AUTOSAR XML (schema 4-0-3)
package /CalibrationComponents
  parameter sw component type SOPR: data-type-mapping=SOPR_CodeDataTypeMappingsSet
    provide port SOPR_Pport: provided-interface=SOPR_if
      provided-com-specs:
        init-value=0, parameter=KeSOPR_I_ChrgCurLmt_Val
        init-value=0, parameter=KeSOPR_I_DschgCurLmt_Val
        init-value=0, parameter=KeSOPR_kE_InitialTotalChargeEnergy
        init-value=0, parameter=KeSOPR_kE_InitialTotalDisChargeEnergy
        init-value=0, parameter=KeSOPR_kE_InitialTotalFeedbackEnergy
        init-value=0, parameter=KeSOPR_kE_OvrdValue_SingleChargeEnergy
        init-value=0, parameter=KeSOPR_kE_OvrdValue_SingleDisChargeEnergy
        init-value=0, parameter=KeSOPR_kE_OvrdValue_SingleFeedbackEnergy
        init-value=0, parameter=KeSOPR_kE_OvrdValue_TotalChargeEnergy
        init-value=0, parameter=KeSOPR_kE_OvrdValue_TotalDisChargeEnergy
        init-value=0, parameter=KeSOPR_kE_OvrdValue_TotalFeedbackEnergy
        init-value=655, parameter=KeSOPR_kE_SingleChargeEnergy_MaxVal
        init-value=0, parameter=KeSOPR_kE_SingleChargeEnergy_minVal
        init-value=655, parameter=KeSOPR_kE_SingleDisChargeEnergy_MaxVal
        init-value=0, parameter=KeSOPR_kE_SingleDisChargeEnergy_minVal
        init-value=655, parameter=KeSOPR_kE_SingleFeedbackEnergy_MaxVal
        init-value=0, parameter=KeSOPR_kE_SingleFeedbackEnergy_minVal
        init-value=104857, parameter=KeSOPR_kE_TotalChargeEnergy_MaxVal
        init-value=0, parameter=KeSOPR_kE_TotalChargeEnergy_minVal
        init-value=1677721, parameter=KeSOPR_kE_TotalDisChargeEnergy_MaxVal
        init-value=0, parameter=KeSOPR_kE_TotalDisChargeEnergy_minVal
        init-value=104857, parameter=KeSOPR_kE_TotalFeedbackEnergy_MaxVal
        init-value=0, parameter=KeSOPR_kE_TotalFeedbackEnergy_minVal
        init-value=0, parameter=KeSOPR_kP_ChrgPwrLmtInst_Val
        init-value=200, parameter=KeSOPR_kP_ChrgPwrLmt_MaxVal
        init-value=0, parameter=KeSOPR_kP_ChrgPwrLmt_Val
        init-value=0, parameter=KeSOPR_kP_ChrgPwrLmt_minVal
        init-value=0, parameter=KeSOPR_kP_DschgPwrLmtInst_Val
        init-value=200, parameter=KeSOPR_kP_DschgPwrLmt_MaxVal
        init-value=0, parameter=KeSOPR_kP_DschgPwrLmt_Val
        init-value=0, parameter=KeSOPR_kP_DschgPwrLmt_minVal
        init-value=9, parameter=KeSOPR_kP_LimitedSOP_Value
        init-value=0, parameter=KeSOPR_kP_OverPower_Reset
        init-value=0.6600000262260437, parameter=KeSOPR_kP_OverPower_Set
        init-value=0, parameter=KeSOPR_kP_PackInstantOutPower_Val
        init-value=0, parameter=KeSOPR_kP_PackInstantRecoveryPower_Val
        init-value=0, parameter=KeSOPR_kP_PackRealTimePower_Val
        init-value=0.5, parameter=KeSOPR_kP_SlewRateLimitPer20ms
        init-value=1.0499999523162842, parameter=KeSOPR_k_CoefRatedPower1_Set
        init-value=1.100000023841858, parameter=KeSOPR_k_CoefRatedPower2_Set
        init-value=1.2000000476837158, parameter=KeSOPR_k_CoefRatedPower3_Set
        init-value=1, parameter=KeSOPR_k_CoefRatedPower_Reset
        init-value=0.20000000298023224, parameter=KeSOPR_t_DTCTimer1_Set
        init-value=0.20000000298023224, parameter=KeSOPR_t_DTCTimer2_Set
        init-value=3, parameter=KeSOPR_t_DTCTimer_Reset
        init-value=0.30000001192092896, parameter=KeSOPR_t_DelayDischarge10Kw
        init-value=0.019999999552965164, parameter=KeSOPR_t_SR_SOPR
        init-value=0, parameter=KeSOPR_b_ChrgCurLmt_Ctrl
        init-value=0, parameter=KeSOPR_b_ChrgPwrLmtInst_Ctrl
        init-value=0, parameter=KeSOPR_b_ChrgPwrLmt_Ctrl
        init-value=0, parameter=KeSOPR_b_DschgCurLmt_Ctrl
        init-value=0, parameter=KeSOPR_b_DschgPwrLmtInst_Ctrl
        init-value=0, parameter=KeSOPR_b_DschgPwrLmt_Ctrl
        init-value=0, parameter=KeSOPR_b_OvrdCond_SingleChargeEnergy
        init-value=0, parameter=KeSOPR_b_OvrdCond_SingleDisChargeEnergy
        init-value=0, parameter=KeSOPR_b_OvrdCond_SingleFeedbackEnergy
        init-value=0, parameter=KeSOPR_b_OvrdCond_TotalChargeEnergy
        init-value=0, parameter=KeSOPR_b_OvrdCond_TotalDisChargeEnergy
        init-value=0, parameter=KeSOPR_b_OvrdCond_TotalFeedbackEnergy
        init-value=0, parameter=KeSOPR_b_PackInstantOutPower_Ctrl
        init-value=0, parameter=KeSOPR_b_PackInstantRecoveryPower_Ctrl
        init-value=0, parameter=KeSOPR_b_PackOverChrgPower{1..3}_flt_En
        init-value=0, parameter=KeSOPR_b_PackOverChrgPower_Rank_CAN_En
        init-value=0, parameter=KeSOPR_b_PackOverDchrgPower{1..3}_flt_En
        init-value=0, parameter=KeSOPR_b_PackOverDchrgPower_Rank_CAN_En
        init-value=0, parameter=KeSOPR_b_PackRealTimePower_Ctrl
        init-value=0, parameter=KeSOPR_k_PackOverChrgPower{1..3}_flt_Val
        init-value=0, parameter=KeSOPR_k_PackOverChrgPower_Rank_CAN_Val
        init-value=0, parameter=KeSOPR_k_PackOverDchrgPower{1..3}_flt_Val
        init-value=0, parameter=KeSOPR_k_PackOverDchrgPower_Rank_CAN_Val
package /SOPR_Code_pkg/SOPR_Code_swc
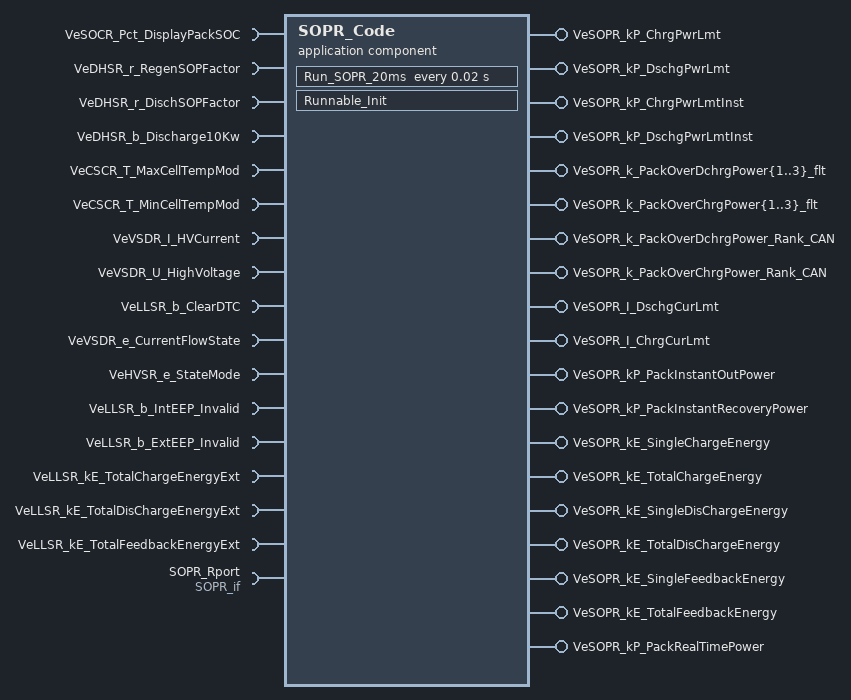
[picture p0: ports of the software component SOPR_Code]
  application sw component type SOPR_Code
    16 x require port:
      VeSOCR_Pct_DisplayPackSOC: nonqueued-receiver-com-spec{data-element=VeSOCR_Pct_DisplayPackSOC, init-value=0}, required-interface=VeSOCR_Pct_DisplayPackSOC
      VeDHSR_r_RegenSOPFactor: nonqueued-receiver-com-spec{data-element=VeDHSR_r_RegenSOPFactor, init-value=0}, required-interface=VeDHSR_r_RegenSOPFactor
      VeDHSR_r_DischSOPFactor: nonqueued-receiver-com-spec{data-element=VeDHSR_r_DischSOPFactor, init-value=0}, required-interface=VeDHSR_r_DischSOPFactor
      VeDHSR_b_Discharge10Kw: nonqueued-receiver-com-spec{data-element=VeDHSR_b_Discharge10Kw, init-value=0}, required-interface=VeDHSR_b_Discharge10Kw
      VeCSCR_T_MaxCellTempMod: nonqueued-receiver-com-spec{data-element=VeCSCR_T_MaxCellTempMod, init-value=0}, required-interface=VeCSCR_T_MaxCellTempMod
      VeCSCR_T_MinCellTempMod: nonqueued-receiver-com-spec{data-element=VeCSCR_T_MinCellTempMod, init-value=0}, required-interface=VeCSCR_T_MinCellTempMod
      VeVSDR_I_HVCurrent: nonqueued-receiver-com-spec{data-element=VeVSDR_I_HVCurrent, init-value=0}, required-interface=VeVSDR_I_HVCurrent
      VeVSDR_U_HighVoltage: nonqueued-receiver-com-spec{data-element=VeVSDR_U_HighVoltage, init-value=0}, required-interface=VeVSDR_U_HighVoltage
      VeLLSR_b_ClearDTC: nonqueued-receiver-com-spec{data-element=VeLLSR_b_ClearDTC, init-value=0}, required-interface=VeLLSR_b_ClearDTC
      VeVSDR_e_CurrentFlowState: nonqueued-receiver-com-spec{data-element=VeVSDR_e_CurrentFlowState, init-value=CeVSDR_e_CurFlowStateInit}, required-interface=VeVSDR_e_CurrentFlowState
      VeHVSR_e_StateMode: nonqueued-receiver-com-spec{data-element=VeHVSR_e_StateMode, init-value=CeHVSR_e_StateModeReserved}, required-interface=VeHVSR_e_StateMode
      VeLLSR_b_IntEEP_Invalid: nonqueued-receiver-com-spec{data-element=VeLLSR_b_IntEEP_Invalid, init-value=0}, required-interface=VeLLSR_b_IntEEP_Invalid
      VeLLSR_b_ExtEEP_Invalid: nonqueued-receiver-com-spec{data-element=VeLLSR_b_ExtEEP_Invalid, init-value=0}, required-interface=VeLLSR_b_ExtEEP_Invalid
      VeLLSR_kE_TotalChargeEnergyExt: nonqueued-receiver-com-spec{data-element=VeLLSR_kE_TotalChargeEnergyExt, init-value=0}, required-interface=VeLLSR_kE_TotalChargeEnergyExt
      VeLLSR_kE_TotalDisChargeEnergyExt: nonqueued-receiver-com-spec{data-element=VeLLSR_kE_TotalDisChargeEnergyExt, init-value=0}, required-interface=VeLLSR_kE_TotalDisChargeEnergyExt
      VeLLSR_kE_TotalFeedbackEnergyExt: nonqueued-receiver-com-spec{data-element=VeLLSR_kE_TotalFeedbackEnergyExt, init-value=0}, required-interface=VeLLSR_kE_TotalFeedbackEnergyExt
    23 x provide port:
      VeSOPR_kP_ChrgPwrLmt: nonqueued-sender-com-spec{data-element=VeSOPR_kP_ChrgPwrLmt, init-value=0}, provided-interface=VeSOPR_kP_ChrgPwrLmt
      VeSOPR_kP_DschgPwrLmt: nonqueued-sender-com-spec{data-element=VeSOPR_kP_DschgPwrLmt, init-value=0}, provided-interface=VeSOPR_kP_DschgPwrLmt
      VeSOPR_kP_ChrgPwrLmtInst: nonqueued-sender-com-spec{data-element=VeSOPR_kP_ChrgPwrLmtInst, init-value=0}, provided-interface=VeSOPR_kP_ChrgPwrLmtInst
      VeSOPR_kP_DschgPwrLmtInst: nonqueued-sender-com-spec{data-element=VeSOPR_kP_DschgPwrLmtInst, init-value=0}, provided-interface=VeSOPR_kP_DschgPwrLmtInst
      VeSOPR_k_PackOverDchrgPower{1..3}_flt: nonqueued-sender-com-spec{data-element=VeSOPR_k_PackOverDchrgPower{1..3}_flt, init-value=0}, provided-interface=VeSOPR_k_PackOverDchrgPower{1..3}_flt
      VeSOPR_k_PackOverChrgPower{1..3}_flt: nonqueued-sender-com-spec{data-element=VeSOPR_k_PackOverChrgPower{1..3}_flt, init-value=0}, provided-interface=VeSOPR_k_PackOverChrgPower{1..3}_flt
      VeSOPR_k_PackOverDchrgPower_Rank_CAN: nonqueued-sender-com-spec{data-element=VeSOPR_k_PackOverDchrgPower_Rank_CAN, init-value=0}, provided-interface=VeSOPR_k_PackOverDchrgPower_Rank_CAN
      VeSOPR_k_PackOverChrgPower_Rank_CAN: nonqueued-sender-com-spec{data-element=VeSOPR_k_PackOverChrgPower_Rank_CAN, init-value=0}, provided-interface=VeSOPR_k_PackOverChrgPower_Rank_CAN
      VeSOPR_I_DschgCurLmt: nonqueued-sender-com-spec{data-element=VeSOPR_I_DschgCurLmt, init-value=0}, provided-interface=VeSOPR_I_DschgCurLmt
      VeSOPR_I_ChrgCurLmt: nonqueued-sender-com-spec{data-element=VeSOPR_I_ChrgCurLmt, init-value=0}, provided-interface=VeSOPR_I_ChrgCurLmt
      VeSOPR_kP_PackInstantOutPower: nonqueued-sender-com-spec{data-element=VeSOPR_kP_PackInstantOutPower, init-value=0}, provided-interface=VeSOPR_kP_PackInstantOutPower
      VeSOPR_kP_PackInstantRecoveryPower: nonqueued-sender-com-spec{data-element=VeSOPR_kP_PackInstantRecoveryPower, init-value=0}, provided-interface=VeSOPR_kP_PackInstantRecoveryPower
      VeSOPR_kE_SingleChargeEnergy: nonqueued-sender-com-spec{data-element=VeSOPR_kE_SingleChargeEnergy, init-value=0}, provided-interface=VeSOPR_kE_SingleChargeEnergy
      VeSOPR_kE_TotalChargeEnergy: nonqueued-sender-com-spec{data-element=VeSOPR_kE_TotalChargeEnergy, init-value=0}, provided-interface=VeSOPR_kE_TotalChargeEnergy
      VeSOPR_kE_SingleDisChargeEnergy: nonqueued-sender-com-spec{data-element=VeSOPR_kE_SingleDisChargeEnergy, init-value=0}, provided-interface=VeSOPR_kE_SingleDisChargeEnergy
      VeSOPR_kE_TotalDisChargeEnergy: nonqueued-sender-com-spec{data-element=VeSOPR_kE_TotalDisChargeEnergy, init-value=0}, provided-interface=VeSOPR_kE_TotalDisChargeEnergy
      VeSOPR_kE_SingleFeedbackEnergy: nonqueued-sender-com-spec{data-element=VeSOPR_kE_SingleFeedbackEnergy, init-value=0}, provided-interface=VeSOPR_kE_SingleFeedbackEnergy
      VeSOPR_kE_TotalFeedbackEnergy: nonqueued-sender-com-spec{data-element=VeSOPR_kE_TotalFeedbackEnergy, init-value=0}, provided-interface=VeSOPR_kE_TotalFeedbackEnergy
      VeSOPR_kP_PackRealTimePower: nonqueued-sender-com-spec{data-element=VeSOPR_kP_PackRealTimePower, init-value=0}, provided-interface=VeSOPR_kP_PackRealTimePower
    require port SOPR_Rport: required-interface=SOPR_if
    behavior SOPR_Code: data-type-mapping=SOPR_CodeDataTypeMappingsSet, handle-termination-and-restart=NO-SUPPORT
      exclusive area EA_NeSOPR_kE_TotalDisChargeEnergy
      exclusive area EA_NeSOPR_kE_TotalFeedbackEnergy
      exclusive area EA_NeSOPR_kE_TotalChargeEnergy
      timing event Event_Run_SOPR_20ms: start-on-event=Run_SOPR_20ms, period=0.02
      per instance memory NeSOPR_kE_TotalDisChargeEnergy: implementation-data-type=Float, type=NeSOPR_kE_TotalDisChargeEnergy_Float, type-definition=Float
      per instance memory NeSOPR_kE_TotalFeedbackEnergy: implementation-data-type=Float, type=NeSOPR_kE_TotalFeedbackEnergy_Float, type-definition=Float
      per instance memory NeSOPR_kE_TotalChargeEnergy: implementation-data-type=Float, type=NeSOPR_kE_TotalChargeEnergy_Float, type-definition=Float
      runnable Runnable_Init: symbol=SOPR_Code_Init
      runnable Run_SOPR_20ms: runs-inside-exclusive-area=[EA_NeSOPR_kE_TotalChargeEnergy, EA_NeSOPR_kE_TotalDisChargeEnergy, EA_NeSOPR_kE_TotalFeedbackEnergy]
        data-read-access:
          16 x access:
            IN_VeCSCR_T_MaxCellTempMod_VeCSCR_T_MaxCellTempMod: accessed-variable=VeCSCR_T_MaxCellTempMod.VeCSCR_T_MaxCellTempMod
            IN_VeCSCR_T_MinCellTempMod_VeCSCR_T_MinCellTempMod: accessed-variable=VeCSCR_T_MinCellTempMod.VeCSCR_T_MinCellTempMod
            IN_VeDHSR_b_Discharge10Kw_VeDHSR_b_Discharge10Kw: accessed-variable=VeDHSR_b_Discharge10Kw.VeDHSR_b_Discharge10Kw
            IN_VeDHSR_r_DischSOPFactor_VeDHSR_r_DischSOPFactor: accessed-variable=VeDHSR_r_DischSOPFactor.VeDHSR_r_DischSOPFactor
            IN_VeDHSR_r_RegenSOPFactor_VeDHSR_r_RegenSOPFactor: accessed-variable=VeDHSR_r_RegenSOPFactor.VeDHSR_r_RegenSOPFactor
            IN_VeHVSR_e_StateMode_VeHVSR_e_StateMode: accessed-variable=VeHVSR_e_StateMode.VeHVSR_e_StateMode
            IN_VeLLSR_b_ClearDTC_VeLLSR_b_ClearDTC: accessed-variable=VeLLSR_b_ClearDTC.VeLLSR_b_ClearDTC
            IN_VeLLSR_b_ExtEEP_Invalid_VeLLSR_b_ExtEEP_Invalid: accessed-variable=VeLLSR_b_ExtEEP_Invalid.VeLLSR_b_ExtEEP_Invalid
            IN_VeLLSR_b_IntEEP_Invalid_VeLLSR_b_IntEEP_Invalid: accessed-variable=VeLLSR_b_IntEEP_Invalid.VeLLSR_b_IntEEP_Invalid
            IN_VeLLSR_kE_TotalChargeEnergyExt_VeLLSR_kE_T_5df67a94075a893a: accessed-variable=VeLLSR_kE_TotalChargeEnergyExt.VeLLSR_kE_TotalChargeEnergyExt
            IN_VeLLSR_kE_TotalDisChargeEnergyExt_VeLLSR_k_0328c4f008460225: accessed-variable=VeLLSR_kE_TotalDisChargeEnergyExt.VeLLSR_kE_TotalDisChargeEnergyExt
            IN_VeLLSR_kE_TotalFeedbackEnergyExt_VeLLSR_kE_f88ecd803695f56f: accessed-variable=VeLLSR_kE_TotalFeedbackEnergyExt.VeLLSR_kE_TotalFeedbackEnergyExt
            IN_VeSOCR_Pct_DisplayPackSOC_VeSOCR_Pct_DisplayPackSOC: accessed-variable=VeSOCR_Pct_DisplayPackSOC.VeSOCR_Pct_DisplayPackSOC
            IN_VeVSDR_I_HVCurrent_VeVSDR_I_HVCurrent: accessed-variable=VeVSDR_I_HVCurrent.VeVSDR_I_HVCurrent
            IN_VeVSDR_U_HighVoltage_VeVSDR_U_HighVoltage: accessed-variable=VeVSDR_U_HighVoltage.VeVSDR_U_HighVoltage
            IN_VeVSDR_e_CurrentFlowState_VeVSDR_e_CurrentFlowState: accessed-variable=VeVSDR_e_CurrentFlowState.VeVSDR_e_CurrentFlowState
        data-send-points:
          23 x access:
            OUT_VeSOPR_kP_ChrgPwrLmt_VeSOPR_kP_ChrgPwrLmt: accessed-variable=VeSOPR_kP_ChrgPwrLmt.VeSOPR_kP_ChrgPwrLmt
            OUT_VeSOPR_kP_DschgPwrLmt_VeSOPR_kP_DschgPwrLmt: accessed-variable=VeSOPR_kP_DschgPwrLmt.VeSOPR_kP_DschgPwrLmt
            OUT_VeSOPR_kP_ChrgPwrLmtInst_VeSOPR_kP_ChrgPwrLmtInst: accessed-variable=VeSOPR_kP_ChrgPwrLmtInst.VeSOPR_kP_ChrgPwrLmtInst
            OUT_VeSOPR_kP_DschgPwrLmtInst_VeSOPR_kP_DschgPwrLmtInst: accessed-variable=VeSOPR_kP_DschgPwrLmtInst.VeSOPR_kP_DschgPwrLmtInst
            OUT_VeSOPR_k_PackOverDchrgPower1_flt_VeSOPR_k_084e043cabe95846: accessed-variable=VeSOPR_k_PackOverDchrgPower1_flt.VeSOPR_k_PackOverDchrgPower1_flt
            OUT_VeSOPR_k_PackOverDchrgPower2_flt_VeSOPR_k_9a63996ecbb8c152: accessed-variable=VeSOPR_k_PackOverDchrgPower2_flt.VeSOPR_k_PackOverDchrgPower2_flt
            OUT_VeSOPR_k_PackOverDchrgPower3_flt_VeSOPR_k_f3b3028557801532: accessed-variable=VeSOPR_k_PackOverDchrgPower3_flt.VeSOPR_k_PackOverDchrgPower3_flt
            OUT_VeSOPR_k_PackOverChrgPower1_flt_VeSOPR_k_bafdb95f1384b1c6: accessed-variable=VeSOPR_k_PackOverChrgPower1_flt.VeSOPR_k_PackOverChrgPower1_flt
            OUT_VeSOPR_k_PackOverChrgPower2_flt_VeSOPR_k_718ddc91b4fe7bda: accessed-variable=VeSOPR_k_PackOverChrgPower2_flt.VeSOPR_k_PackOverChrgPower2_flt
            OUT_VeSOPR_k_PackOverChrgPower3_flt_VeSOPR_k_da0a8855b1c881eb: accessed-variable=VeSOPR_k_PackOverChrgPower3_flt.VeSOPR_k_PackOverChrgPower3_flt
            OUT_VeSOPR_k_PackOverDchrgPower_Rank_CAN_VeSO_a530ebaf238aaa7d: accessed-variable=VeSOPR_k_PackOverDchrgPower_Rank_CAN.VeSOPR_k_PackOverDchrgPower_Rank_CAN
            OUT_VeSOPR_k_PackOverChrgPower_Rank_CAN_VeSOP_13a80a9a90f45aca: accessed-variable=VeSOPR_k_PackOverChrgPower_Rank_CAN.VeSOPR_k_PackOverChrgPower_Rank_CAN
            OUT_VeSOPR_I_DschgCurLmt_VeSOPR_I_DschgCurLmt: accessed-variable=VeSOPR_I_DschgCurLmt.VeSOPR_I_DschgCurLmt
            OUT_VeSOPR_I_ChrgCurLmt_VeSOPR_I_ChrgCurLmt: accessed-variable=VeSOPR_I_ChrgCurLmt.VeSOPR_I_ChrgCurLmt
            OUT_VeSOPR_kP_PackInstantOutPower_VeSOPR_kP_P_323630c1f9671d55: accessed-variable=VeSOPR_kP_PackInstantOutPower.VeSOPR_kP_PackInstantOutPower
            OUT_VeSOPR_kP_PackInstantRecoveryPower_VeSOPR_f42613d02ba8428d: accessed-variable=VeSOPR_kP_PackInstantRecoveryPower.VeSOPR_kP_PackInstantRecoveryPower
            OUT_VeSOPR_kE_SingleChargeEnergy_VeSOPR_kE_SingleChargeEnergy: accessed-variable=VeSOPR_kE_SingleChargeEnergy.VeSOPR_kE_SingleChargeEnergy
            OUT_VeSOPR_kE_TotalChargeEnergy_VeSOPR_kE_TotalChargeEnergy: accessed-variable=VeSOPR_kE_TotalChargeEnergy.VeSOPR_kE_TotalChargeEnergy
            OUT_VeSOPR_kE_SingleDisChargeEnergy_VeSOPR_kE_0744e4b55030a507: accessed-variable=VeSOPR_kE_SingleDisChargeEnergy.VeSOPR_kE_SingleDisChargeEnergy
            OUT_VeSOPR_kE_TotalDisChargeEnergy_VeSOPR_kE_ed764fddd891b2d9: accessed-variable=VeSOPR_kE_TotalDisChargeEnergy.VeSOPR_kE_TotalDisChargeEnergy
            OUT_VeSOPR_kE_SingleFeedbackEnergy_VeSOPR_kE_44262c0c73e49981: accessed-variable=VeSOPR_kE_SingleFeedbackEnergy.VeSOPR_kE_SingleFeedbackEnergy
            OUT_VeSOPR_kE_TotalFeedbackEnergy_VeSOPR_kE_T_c839511a63296a08: accessed-variable=VeSOPR_kE_TotalFeedbackEnergy.VeSOPR_kE_TotalFeedbackEnergy
            OUT_VeSOPR_kP_PackRealTimePower_VeSOPR_kP_PackRealTimePower: accessed-variable=VeSOPR_kP_PackRealTimePower.VeSOPR_kP_PackRealTimePower
        75 x parameter access:
          CALPRM_SOPR_Rport_KeSOPR_I_ChrgCurLmt_Val: accessed-parameter=SOPR_Rport.KeSOPR_I_ChrgCurLmt_Val
          CALPRM_SOPR_Rport_KeSOPR_I_DschgCurLmt_Val: accessed-parameter=SOPR_Rport.KeSOPR_I_DschgCurLmt_Val
          CALPRM_SOPR_Rport_KeSOPR_b_ChrgCurLmt_Ctrl: accessed-parameter=SOPR_Rport.KeSOPR_b_ChrgCurLmt_Ctrl
          CALPRM_SOPR_Rport_KeSOPR_b_ChrgPwrLmtInst_Ctrl: accessed-parameter=SOPR_Rport.KeSOPR_b_ChrgPwrLmtInst_Ctrl
          CALPRM_SOPR_Rport_KeSOPR_b_ChrgPwrLmt_Ctrl: accessed-parameter=SOPR_Rport.KeSOPR_b_ChrgPwrLmt_Ctrl
          CALPRM_SOPR_Rport_KeSOPR_b_DschgCurLmt_Ctrl: accessed-parameter=SOPR_Rport.KeSOPR_b_DschgCurLmt_Ctrl
          CALPRM_SOPR_Rport_KeSOPR_b_DschgPwrLmtInst_Ctrl: accessed-parameter=SOPR_Rport.KeSOPR_b_DschgPwrLmtInst_Ctrl
          CALPRM_SOPR_Rport_KeSOPR_b_DschgPwrLmt_Ctrl: accessed-parameter=SOPR_Rport.KeSOPR_b_DschgPwrLmt_Ctrl
          CALPRM_SOPR_Rport_KeSOPR_b_OvrdCond_SingleChargeEnergy: accessed-parameter=SOPR_Rport.KeSOPR_b_OvrdCond_SingleChargeEnergy
          CALPRM_SOPR_Rport_KeSOPR_b_OvrdCond_SingleDisChargeEnergy: accessed-parameter=SOPR_Rport.KeSOPR_b_OvrdCond_SingleDisChargeEnergy
          CALPRM_SOPR_Rport_KeSOPR_b_OvrdCond_SingleFeedbackEnergy: accessed-parameter=SOPR_Rport.KeSOPR_b_OvrdCond_SingleFeedbackEnergy
          CALPRM_SOPR_Rport_KeSOPR_b_OvrdCond_TotalChargeEnergy: accessed-parameter=SOPR_Rport.KeSOPR_b_OvrdCond_TotalChargeEnergy
          CALPRM_SOPR_Rport_KeSOPR_b_OvrdCond_TotalDisChargeEnergy: accessed-parameter=SOPR_Rport.KeSOPR_b_OvrdCond_TotalDisChargeEnergy
          CALPRM_SOPR_Rport_KeSOPR_b_OvrdCond_TotalFeedbackEnergy: accessed-parameter=SOPR_Rport.KeSOPR_b_OvrdCond_TotalFeedbackEnergy
          CALPRM_SOPR_Rport_KeSOPR_b_PackInstantOutPower_Ctrl: accessed-parameter=SOPR_Rport.KeSOPR_b_PackInstantOutPower_Ctrl
          CALPRM_SOPR_Rport_KeSOPR_b_PackInstantRecoveryPower_Ctrl: accessed-parameter=SOPR_Rport.KeSOPR_b_PackInstantRecoveryPower_Ctrl
          CALPRM_SOPR_Rport_KeSOPR_b_PackOverChrgPower{1..3}_flt_En: accessed-parameter=SOPR_Rport.KeSOPR_b_PackOverChrgPower{1..3}_flt_En
          CALPRM_SOPR_Rport_KeSOPR_b_PackOverChrgPower_Rank_CAN_En: accessed-parameter=SOPR_Rport.KeSOPR_b_PackOverChrgPower_Rank_CAN_En
          CALPRM_SOPR_Rport_KeSOPR_b_PackOverDchrgPower{1..3}_flt_En: accessed-parameter=SOPR_Rport.KeSOPR_b_PackOverDchrgPower{1..3}_flt_En
          CALPRM_SOPR_Rport_KeSOPR_b_PackOverDchrgPower_Rank_CAN_En: accessed-parameter=SOPR_Rport.KeSOPR_b_PackOverDchrgPower_Rank_CAN_En
          CALPRM_SOPR_Rport_KeSOPR_b_PackRealTimePower_Ctrl: accessed-parameter=SOPR_Rport.KeSOPR_b_PackRealTimePower_Ctrl
          CALPRM_SOPR_Rport_KeSOPR_kE_OvrdValue_SingleChargeEnergy: accessed-parameter=SOPR_Rport.KeSOPR_kE_OvrdValue_SingleChargeEnergy
          CALPRM_SOPR_Rport_KeSOPR_kE_OvrdValue_SingleDisChargeEnergy: accessed-parameter=SOPR_Rport.KeSOPR_kE_OvrdValue_SingleDisChargeEnergy
          CALPRM_SOPR_Rport_KeSOPR_kE_OvrdValue_SingleFeedbackEnergy: accessed-parameter=SOPR_Rport.KeSOPR_kE_OvrdValue_SingleFeedbackEnergy
          CALPRM_SOPR_Rport_KeSOPR_kE_OvrdValue_TotalChargeEnergy: accessed-parameter=SOPR_Rport.KeSOPR_kE_OvrdValue_TotalChargeEnergy
          CALPRM_SOPR_Rport_KeSOPR_kE_OvrdValue_TotalDisChargeEnergy: accessed-parameter=SOPR_Rport.KeSOPR_kE_OvrdValue_TotalDisChargeEnergy
          CALPRM_SOPR_Rport_KeSOPR_kE_OvrdValue_TotalFeedbackEnergy: accessed-parameter=SOPR_Rport.KeSOPR_kE_OvrdValue_TotalFeedbackEnergy
          CALPRM_SOPR_Rport_KeSOPR_kE_SingleChargeEnergy_MaxVal: accessed-parameter=SOPR_Rport.KeSOPR_kE_SingleChargeEnergy_MaxVal
          CALPRM_SOPR_Rport_KeSOPR_kE_SingleChargeEnergy_minVal: accessed-parameter=SOPR_Rport.KeSOPR_kE_SingleChargeEnergy_minVal
          CALPRM_SOPR_Rport_KeSOPR_kE_SingleDisChargeEnergy_MaxVal: accessed-parameter=SOPR_Rport.KeSOPR_kE_SingleDisChargeEnergy_MaxVal
          CALPRM_SOPR_Rport_KeSOPR_kE_SingleDisChargeEnergy_minVal: accessed-parameter=SOPR_Rport.KeSOPR_kE_SingleDisChargeEnergy_minVal
          CALPRM_SOPR_Rport_KeSOPR_kE_SingleFeedbackEnergy_MaxVal: accessed-parameter=SOPR_Rport.KeSOPR_kE_SingleFeedbackEnergy_MaxVal
          CALPRM_SOPR_Rport_KeSOPR_kE_SingleFeedbackEnergy_minVal: accessed-parameter=SOPR_Rport.KeSOPR_kE_SingleFeedbackEnergy_minVal
          CALPRM_SOPR_Rport_KeSOPR_kE_TotalChargeEnergy_MaxVal: accessed-parameter=SOPR_Rport.KeSOPR_kE_TotalChargeEnergy_MaxVal
          CALPRM_SOPR_Rport_KeSOPR_kE_TotalChargeEnergy_minVal: accessed-parameter=SOPR_Rport.KeSOPR_kE_TotalChargeEnergy_minVal
          CALPRM_SOPR_Rport_KeSOPR_kE_TotalDisChargeEnergy_MaxVal: accessed-parameter=SOPR_Rport.KeSOPR_kE_TotalDisChargeEnergy_MaxVal
          CALPRM_SOPR_Rport_KeSOPR_kE_TotalDisChargeEnergy_minVal: accessed-parameter=SOPR_Rport.KeSOPR_kE_TotalDisChargeEnergy_minVal
          CALPRM_SOPR_Rport_KeSOPR_kE_TotalFeedbackEnergy_MaxVal: accessed-parameter=SOPR_Rport.KeSOPR_kE_TotalFeedbackEnergy_MaxVal
          CALPRM_SOPR_Rport_KeSOPR_kE_TotalFeedbackEnergy_minVal: accessed-parameter=SOPR_Rport.KeSOPR_kE_TotalFeedbackEnergy_minVal
          CALPRM_SOPR_Rport_KeSOPR_kP_ChrgPwrLmtInst_Val: accessed-parameter=SOPR_Rport.KeSOPR_kP_ChrgPwrLmtInst_Val
          CALPRM_SOPR_Rport_KeSOPR_kP_ChrgPwrLmt_MaxVal: accessed-parameter=SOPR_Rport.KeSOPR_kP_ChrgPwrLmt_MaxVal
          CALPRM_SOPR_Rport_KeSOPR_kP_ChrgPwrLmt_Val: accessed-parameter=SOPR_Rport.KeSOPR_kP_ChrgPwrLmt_Val
          CALPRM_SOPR_Rport_KeSOPR_kP_ChrgPwrLmt_minVal: accessed-parameter=SOPR_Rport.KeSOPR_kP_ChrgPwrLmt_minVal
          CALPRM_SOPR_Rport_KeSOPR_kP_DschgPwrLmtInst_Val: accessed-parameter=SOPR_Rport.KeSOPR_kP_DschgPwrLmtInst_Val
          CALPRM_SOPR_Rport_KeSOPR_kP_DschgPwrLmt_MaxVal: accessed-parameter=SOPR_Rport.KeSOPR_kP_DschgPwrLmt_MaxVal
          CALPRM_SOPR_Rport_KeSOPR_kP_DschgPwrLmt_Val: accessed-parameter=SOPR_Rport.KeSOPR_kP_DschgPwrLmt_Val
          CALPRM_SOPR_Rport_KeSOPR_kP_DschgPwrLmt_minVal: accessed-parameter=SOPR_Rport.KeSOPR_kP_DschgPwrLmt_minVal
          CALPRM_SOPR_Rport_KeSOPR_kP_LimitedSOP_Value: accessed-parameter=SOPR_Rport.KeSOPR_kP_LimitedSOP_Value
          CALPRM_SOPR_Rport_KeSOPR_kP_OverPower_Reset: accessed-parameter=SOPR_Rport.KeSOPR_kP_OverPower_Reset
          CALPRM_SOPR_Rport_KeSOPR_kP_OverPower_Set: accessed-parameter=SOPR_Rport.KeSOPR_kP_OverPower_Set
          CALPRM_SOPR_Rport_KeSOPR_kP_PackInstantOutPower_Val: accessed-parameter=SOPR_Rport.KeSOPR_kP_PackInstantOutPower_Val
          CALPRM_SOPR_Rport_KeSOPR_kP_PackInstantRecoveryPower_Val: accessed-parameter=SOPR_Rport.KeSOPR_kP_PackInstantRecoveryPower_Val
          CALPRM_SOPR_Rport_KeSOPR_kP_PackRealTimePower_Val: accessed-parameter=SOPR_Rport.KeSOPR_kP_PackRealTimePower_Val
          CALPRM_SOPR_Rport_KeSOPR_kP_SlewRateLimitPer20ms: accessed-parameter=SOPR_Rport.KeSOPR_kP_SlewRateLimitPer20ms
          CALPRM_SOPR_Rport_KeSOPR_k_CoefRatedPower{1..3}_Set: accessed-parameter=SOPR_Rport.KeSOPR_k_CoefRatedPower{1..3}_Set
          CALPRM_SOPR_Rport_KeSOPR_k_CoefRatedPower_Reset: accessed-parameter=SOPR_Rport.KeSOPR_k_CoefRatedPower_Reset
          CALPRM_SOPR_Rport_KeSOPR_k_PackOverChrgPower{1..3}_flt_Val: accessed-parameter=SOPR_Rport.KeSOPR_k_PackOverChrgPower{1..3}_flt_Val
          CALPRM_SOPR_Rport_KeSOPR_k_PackOverChrgPower_Rank_CAN_Val: accessed-parameter=SOPR_Rport.KeSOPR_k_PackOverChrgPower_Rank_CAN_Val
          CALPRM_SOPR_Rport_KeSOPR_k_PackOverDchrgPower{1..3}_flt_Val: accessed-parameter=SOPR_Rport.KeSOPR_k_PackOverDchrgPower{1..3}_flt_Val
          CALPRM_SOPR_Rport_KeSOPR_k_PackOverDchrgPower_Rank_CAN_Val: accessed-parameter=SOPR_Rport.KeSOPR_k_PackOverDchrgPower_Rank_CAN_Val
          CALPRM_SOPR_Rport_KeSOPR_t_DTCTimer1_Set: accessed-parameter=SOPR_Rport.KeSOPR_t_DTCTimer1_Set
          CALPRM_SOPR_Rport_KeSOPR_t_DTCTimer2_Set: accessed-parameter=SOPR_Rport.KeSOPR_t_DTCTimer2_Set
          CALPRM_SOPR_Rport_KeSOPR_t_DTCTimer_Reset: accessed-parameter=SOPR_Rport.KeSOPR_t_DTCTimer_Reset
          CALPRM_SOPR_Rport_KeSOPR_t_DelayDischarge10Kw: accessed-parameter=SOPR_Rport.KeSOPR_t_DelayDischarge10Kw
          CALPRM_SOPR_Rport_KeSOPR_t_SR_SOPR: accessed-parameter=SOPR_Rport.KeSOPR_t_SR_SOPR
      swc service dependency SwcNv_NeSOPR_kE_TotalDisChargeEnergy: assigned-datas=role-based-data-assignment={role=ramBlock, used-pim=NeSOPR_kE_TotalDisChargeEnergy}
        service-needs:
          nv block needs SwcNv_NeSOPR_kE_TotalDisChargeEnergy: restore-at-start=true, store-at-shutdown=true
      swc service dependency SwcNv_NeSOPR_kE_TotalFeedbackEnergy: assigned-datas=role-based-data-assignment={role=ramBlock, used-pim=NeSOPR_kE_TotalFeedbackEnergy}
        service-needs:
          nv block needs SwcNv_NeSOPR_kE_TotalFeedbackEnergy: restore-at-start=true, store-at-shutdown=true
      swc service dependency SwcNv_NeSOPR_kE_TotalChargeEnergy: assigned-datas=role-based-data-assignment={role=ramBlock, used-pim=NeSOPR_kE_TotalChargeEnergy}
        service-needs:
          nv block needs SwcNv_NeSOPR_kE_TotalChargeEnergy: restore-at-start=true, store-at-shutdown=true
